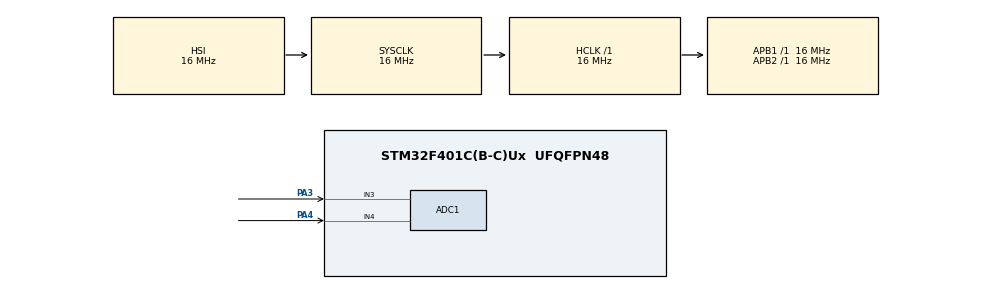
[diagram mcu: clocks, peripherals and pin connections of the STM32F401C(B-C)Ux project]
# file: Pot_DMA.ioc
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ADC1.Channel-1\#ChannelRegularConversion=ADC_CHANNEL_3
ADC1.Channel-2\#ChannelRegularConversion=ADC_CHANNEL_4
ADC1.ContinuousConvMode=ENABLE
ADC1.DMAContinuousRequests=ENABLE
ADC1.EOCSelection=ADC_EOC_SINGLE_CONV
ADC1.EnableAnalogWatchDog=false
ADC1.NbrOfConversion=2
ADC1.NbrOfConversionFlag=1
ADC1.Rank-1\#ChannelRegularConversion=1
ADC1.Rank-2\#ChannelRegularConversion=2
ADC1.SamplingTime-1\#ChannelRegularConversion=ADC_SAMPLETIME_3CYCLES
ADC1.SamplingTime-2\#ChannelRegularConversion=ADC_SAMPLETIME_3CYCLES
ADC1.master=1
Dma.ADC1.0.Direction=DMA_PERIPH_TO_MEMORY
Dma.ADC1.0.FIFOMode=DMA_FIFOMODE_ENABLE
Dma.ADC1.0.FIFOThreshold=DMA_FIFO_THRESHOLD_FULL
Dma.ADC1.0.Instance=DMA2_Stream0
Dma.ADC1.0.MemBurst=DMA_MBURST_SINGLE
Dma.ADC1.0.MemDataAlignment=DMA_MDATAALIGN_HALFWORD
Dma.ADC1.0.MemInc=DMA_MINC_ENABLE
Dma.ADC1.0.Mode=DMA_NORMAL
Dma.ADC1.0.PeriphBurst=DMA_PBURST_SINGLE
Dma.ADC1.0.PeriphDataAlignment=DMA_PDATAALIGN_HALFWORD
Dma.ADC1.0.PeriphInc=DMA_PINC_DISABLE
Dma.ADC1.0.Priority=DMA_PRIORITY_LOW
Dma.Request0=ADC1
Mcu.Family=STM32F4
Mcu.Name=STM32F401C(B-C)Ux
Mcu.Package=UFQFPN48
NVIC.DMA2_Stream0_IRQn=true\:0\:0\:false\:false\:true\:false\:true\:true
NVIC.PriorityGroup=NVIC_PRIORITYGROUP_4
NVIC.TIM5_IRQn=true\:15\:0\:false\:false\:true\:false\:true\:true
NVIC.TimeBase=TIM5_IRQn
NVIC.TimeBaseIP=TIM5
PA3.Signal=ADCx_IN3
PA4.Signal=ADCx_IN4
ProjectManager.HeapSize=0x200
ProjectManager.StackSize=0x400
ProjectManager.TargetToolchain=STM32CubeIDE
RCC.AHBFreq_Value=16000000
RCC.APB1Freq_Value=16000000
RCC.APB2Freq_Value=16000000
RCC.CortexFreq_Value=16000000
RCC.HSE_VALUE=25000000
RCC.HSI_VALUE=16000000
RCC.LSE_VALUE=32768
RCC.SYSCLKFreq_VALUE=16000000
RCC.VCOOutputFreq_Value=192000000
SH.ADCx_IN3.0=ADC1_IN3,IN3
SH.ADCx_IN4.0=ADC1_IN4,IN4
VP_SYS_VS_tim5.Mode=TIM5
board=custom

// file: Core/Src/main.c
/* USER CODE BEGIN Header */
/**
  ******************************************************************************
  * @file           : main.c
  * @brief          : Main program body
  ******************************************************************************
  * @attention
  *
  * Copyright (c) 2023 STMicroelectronics.
  * All rights reserved.
  *
  * This software is licensed under terms that can be found in the LICENSE file
  * in the root directory of this software component.
  * If no LICENSE file comes with this software, it is provided AS-IS.
  *
  ******************************************************************************
  */
/* USER CODE END Header */
#include "main.h"

ADC_HandleTypeDef hadc1;
DMA_HandleTypeDef hdma_adc1;

/* USER CODE BEGIN PV */
int adc1, adc2;
volatile uint16_t adc_result[2];
const int adc_channel_count = sizeof(adc_result) / sizeof(adc_result[0]);
volatile int adc_conversion_complete = 0, adc_half_conversion_complete = 0;
/* USER CODE END PV */

void SystemClock_Config(void);
static void MX_GPIO_Init(void);
static void MX_DMA_Init(void);
static void MX_ADC1_Init(void);

int main(void)
{

  /* MCU Configuration--------------------------------------------------------*/

  /* Reset of all peripherals, Initializes the Flash interface and the Systick. */

	HAL_Init();

  /* Configure the system clock */
  SystemClock_Config();

  /* Initialize all configured peripherals */
  MX_GPIO_Init();
  MX_DMA_Init();
  MX_ADC1_Init();

  /* Infinite loop */
  /* USER CODE BEGIN WHILE */
  while (1)
  {
	  HAL_ADC_Start_DMA(&hadc1, (uint32_t*)adc_result, adc_channel_count);
	  if(adc_conversion_complete == 1){
		  adc1 = adc_result[0];
		  adc2 = adc_result[1];
	  	  adc_conversion_complete = 0;
	  }
	  HAL_Delay(100);
    /* USER CODE END WHILE */

  }
}

void SystemClock_Config(void)
{
  RCC_OscInitTypeDef RCC_OscInitStruct = {0};
  RCC_ClkInitTypeDef RCC_ClkInitStruct = {0};

  /** Configure the main internal regulator output voltage
  */
  __HAL_RCC_PWR_CLK_ENABLE();
  __HAL_PWR_VOLTAGESCALING_CONFIG(PWR_REGULATOR_VOLTAGE_SCALE2);

  /** Initializes the RCC Oscillators according to the specified parameters
  * in the RCC_OscInitTypeDef structure.
  */
  RCC_OscInitStruct.OscillatorType = RCC_OSCILLATORTYPE_HSI;
  RCC_OscInitStruct.HSIState = RCC_HSI_ON;
  RCC_OscInitStruct.HSICalibrationValue = RCC_HSICALIBRATION_DEFAULT;
  RCC_OscInitStruct.PLL.PLLState = RCC_PLL_NONE;
  if (HAL_RCC_OscConfig(&RCC_OscInitStruct) != HAL_OK)
  {
    Error_Handler();
  }

  /** Initializes the CPU, AHB and APB buses clocks
  */
  RCC_ClkInitStruct.ClockType = RCC_CLOCKTYPE_HCLK|RCC_CLOCKTYPE_SYSCLK
                              |RCC_CLOCKTYPE_PCLK1|RCC_CLOCKTYPE_PCLK2;
  RCC_ClkInitStruct.SYSCLKSource = RCC_SYSCLKSOURCE_HSI;
  RCC_ClkInitStruct.AHBCLKDivider = RCC_SYSCLK_DIV1;
  RCC_ClkInitStruct.APB1CLKDivider = RCC_HCLK_DIV1;
  RCC_ClkInitStruct.APB2CLKDivider = RCC_HCLK_DIV1;

  if (HAL_RCC_ClockConfig(&RCC_ClkInitStruct, FLASH_LATENCY_0) != HAL_OK)
  {
    Error_Handler();
  }
}

static void MX_ADC1_Init(void)
{

  ADC_ChannelConfTypeDef sConfig = {0};

  /** Configure the global features of the ADC (Clock, Resolution, Data Alignment and number of conversion)
  */
  hadc1.Instance = ADC1;
  hadc1.Init.ClockPrescaler = ADC_CLOCK_SYNC_PCLK_DIV2;
  hadc1.Init.Resolution = ADC_RESOLUTION_12B;
  hadc1.Init.ScanConvMode = ENABLE;
  hadc1.Init.ContinuousConvMode = ENABLE;
  hadc1.Init.DiscontinuousConvMode = DISABLE;
  hadc1.Init.ExternalTrigConvEdge = ADC_EXTERNALTRIGCONVEDGE_NONE;
  hadc1.Init.ExternalTrigConv = ADC_SOFTWARE_START;
  hadc1.Init.DataAlign = ADC_DATAALIGN_RIGHT;
  hadc1.Init.NbrOfConversion = 2;
  hadc1.Init.DMAContinuousRequests = ENABLE;
  hadc1.Init.EOCSelection = ADC_EOC_SINGLE_CONV;
  if (HAL_ADC_Init(&hadc1) != HAL_OK)
  {
    Error_Handler();
  }

  /** Configure for the selected ADC regular channel its corresponding rank in the sequencer and its sample time.
  */
  sConfig.Channel = ADC_CHANNEL_3;
  sConfig.Rank = 1;
  sConfig.SamplingTime = ADC_SAMPLETIME_3CYCLES;
  if (HAL_ADC_ConfigChannel(&hadc1, &sConfig) != HAL_OK)
  {
    Error_Handler();
  }

  /** Configure for the selected ADC regular channel its corresponding rank in the sequencer and its sample time.
  */
  sConfig.Channel = ADC_CHANNEL_4;
  sConfig.Rank = 2;
  if (HAL_ADC_ConfigChannel(&hadc1, &sConfig) != HAL_OK)
  {
    Error_Handler();
  }

}

static void MX_DMA_Init(void)
{

  /* DMA controller clock enable */
  __HAL_RCC_DMA2_CLK_ENABLE();

  /* DMA interrupt init */
  /* DMA2_Stream0_IRQn interrupt configuration */
  HAL_NVIC_SetPriority(DMA2_Stream0_IRQn, 0, 0);
  HAL_NVIC_EnableIRQ(DMA2_Stream0_IRQn);

}

static void MX_GPIO_Init(void)
{

  /* GPIO Ports Clock Enable */
  __HAL_RCC_GPIOA_CLK_ENABLE();

}

/* USER CODE BEGIN 4 */
void HAL_ADC_ConvCpltCallback(ADC_HandleTypeDef* hadc){
	adc_conversion_complete = 1;
}
/* USER CODE END 4 */

void HAL_TIM_PeriodElapsedCallback(TIM_HandleTypeDef *htim)
{
  if (htim->Instance == TIM5) {
    HAL_IncTick();
  }
}

void Error_Handler(void)
{
  __disable_irq();
  while (1)
  {
  }
}
